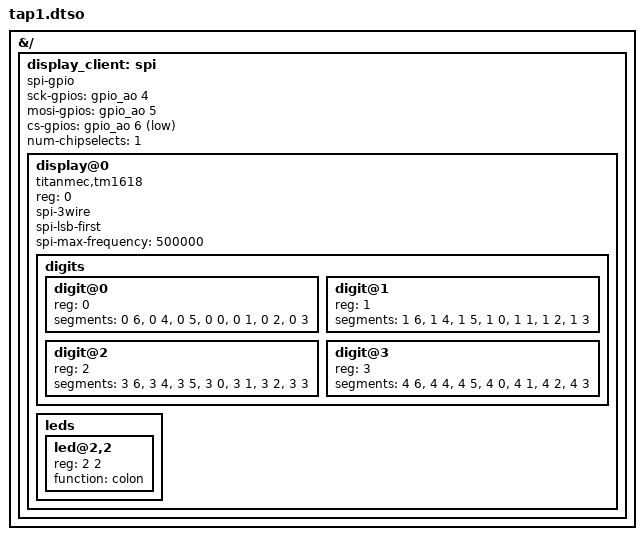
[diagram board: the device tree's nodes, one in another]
/dts-v1/;
/plugin/;

#include <dt-bindings/gpio/gpio.h>
#include <dt-bindings/leds/common.h>

&{/} {

	display_client: spi {
		#address-cells = <1>;
		#size-cells = <0>;
		compatible = "spi-gpio";
		sck-gpios = <&gpio_ao 4 GPIO_ACTIVE_HIGH>;
		mosi-gpios = <&gpio_ao 5 GPIO_ACTIVE_HIGH>;
		cs-gpios = <&gpio_ao 6 GPIO_ACTIVE_LOW>;
		num-chipselects = <1>;

		display@0 {
			compatible = "titanmec,tm1618";
			reg = <0>;
			spi-3wire;
			spi-lsb-first;
			spi-max-frequency = <500000>;

			digits {
				#address-cells = <1>;
				#size-cells = <0>;
				digit@0 {
					reg = <0>;
					segments = <0 6>,
						   <0 4>,
						   <0 5>,
						   <0 0>,
						   <0 1>,
						   <0 2>,
						   <0 3>;
				};
				digit@1 {
					reg = <1>;
					segments = <1 6>,
						   <1 4>,
						   <1 5>,
						   <1 0>,
						   <1 1>,
						   <1 2>,
						   <1 3>;
				};
				digit@2 {
					reg = <2>;
					segments = <3 6>,
						   <3 4>,
						   <3 5>,
						   <3 0>,
						   <3 1>,
						   <3 2>,
						   <3 3>;
				};
				digit@3 {
					reg = <3>;
					segments = <4 6>,
						   <4 4>,
						   <4 5>,
						   <4 0>,
						   <4 1>,
						   <4 2>,
						   <4 3>;
				};
			};

			leds {
				#address-cells = <2>;
				#size-cells = <0>;
				led@2,2 {
					reg = <2 2>;
					function = "colon";
				};
			};
		};
	};
};
